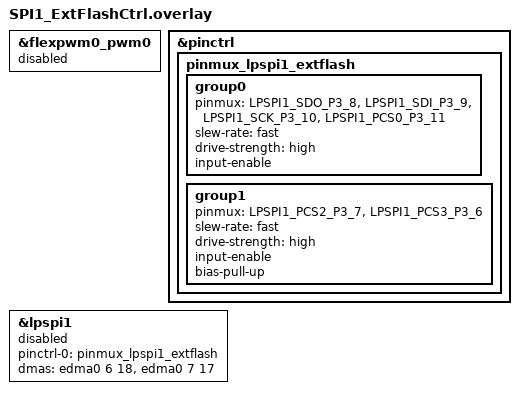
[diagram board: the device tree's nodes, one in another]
#include <nxp/mcx/MCXA156VLL-pinctrl.h>

&flexpwm0_pwm0 {
    status = "disabled";
};

&pinctrl {
    pinmux_lpspi1_extflash: pinmux_lpspi1_extflash {
        
        group0 {
            pinmux = <LPSPI1_SDO_P3_8>,
                    <LPSPI1_SDI_P3_9>,
                    <LPSPI1_SCK_P3_10>,
                    <LPSPI1_PCS0_P3_11>;

            slew-rate = "fast";
            drive-strength = "high";
            input-enable;
        };

        group1 {
            pinmux = <LPSPI1_PCS2_P3_7>,
                     <LPSPI1_PCS3_P3_6>;

            slew-rate = "fast";
            drive-strength = "high";
            input-enable;
            bias-pull-up;
        };        
    };
};

&lpspi1{
    /* LPSPI1 is owned and initialized directly by NXP_SPI_API. */
    status = "disabled";

    pinctrl-0 = <&pinmux_lpspi1_extflash>;
    pinctrl-names = "default";

    dmas = <&edma0 6 18>,
           <&edma0 7 17>;
    dma-names = "tx", "rx";
};
